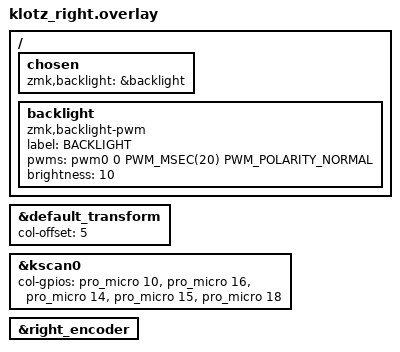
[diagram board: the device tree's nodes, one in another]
/*
 * Copyright (c) 2020 Pete Johanson
 *
 * SPDX-License-Identifier: MIT
 */

#include "klotz.dtsi"

/ {
    chosen {
        zmk,backlight = &backlight;
    };

    backlight: backlight {
        compatible = "zmk,backlight-pwm";
        label = "BACKLIGHT";
        pwms = <&pwm0 0 PWM_MSEC(20) PWM_POLARITY_NORMAL>;
        // Passe die Werte ggf. an dein Board an!
        brightness = <10>;
    };
};

&default_transform {
	col-offset = <5>;
};

&kscan0 {
	col-gpios
		= <&pro_micro 10 GPIO_ACTIVE_HIGH>
		, <&pro_micro 16 GPIO_ACTIVE_HIGH>
		, <&pro_micro 14 GPIO_ACTIVE_HIGH>
		, <&pro_micro 15 GPIO_ACTIVE_HIGH>
		, <&pro_micro 18 GPIO_ACTIVE_HIGH>
		;
};

&right_encoder {
	status = "okay";
};
